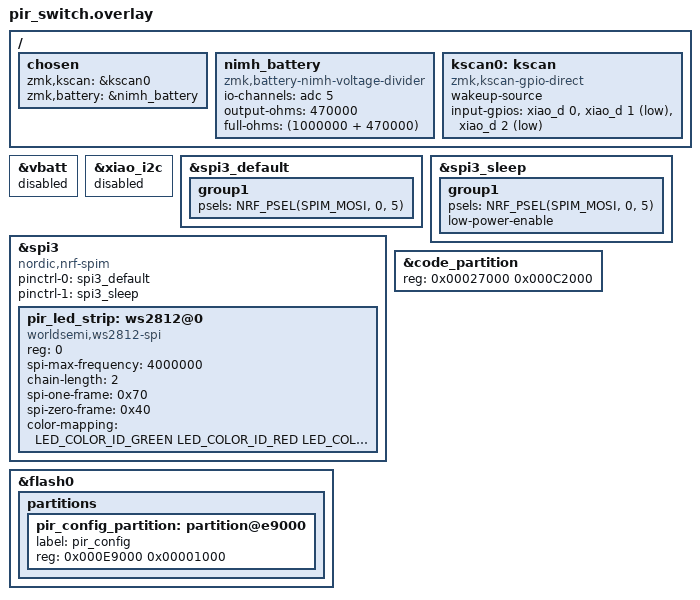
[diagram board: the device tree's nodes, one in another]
/*
 * ハードウェア定義（デバイスツリー = 「どのピンに何がつながっているか」を書くファイル）
 *
 * 配線:
 *   AM312 VCC -> XIAO BLE 3V3
 *   AM312 GND -> XIAO BLE GND
 *   AM312 OUT -> XIAO BLE D0
 *   スイッチA -> D1 と GND の間（モード1・緑）
 *   スイッチB -> D2 と GND の間（モード2・青）
 *   LED1（スイッチAの下、SK6812MINI-E）: VDD -> 3V3, GND -> GND, DIN -> D5
 *   LED2（スイッチBの下、SK6812MINI-E）: VDD -> 3V3, GND -> GND, DIN -> LED1 の DOUT
 *   昇圧モジュール（aaa-boost-module-v2）:
 *     GND -> GND, 5V -> 5V, SNS -> D3, MCU -> BAT+（XIAO 裏面）, BAT -> 電源スイッチ -> 電池+
 */

#include <dt-bindings/led/led.h>

/ {
    chosen {
        zmk,kscan = &kscan0;
        zmk,battery = &nimh_battery;
    };

    /*
     * 電池残量（エネループ1本）
     * 昇圧モジュールの SNS 端子 = 電池電圧 × 470k / (1M + 470k) を D3（P0.29 = AIN5）で測る。
     * XIAO 標準の vbatt は BAT+ の電圧（= 昇圧後の一定電圧）を測るため、残量の目安にならないので使わない。
     */
    nimh_battery: nimh_battery {
        compatible = "zmk,battery-nimh-voltage-divider";
        io-channels = <&adc 5>;
        output-ohms = <470000>;
        full-ohms = <(1000000 + 470000)>;
    };

    kscan0: kscan {
        /* キーマトリクスを使わず、1ピン = 1キーとして読む方式 */
        compatible = "zmk,kscan-gpio-direct";

        /* 省電力スリープ中でも、このピンの変化で起きるようにする */
        wakeup-source;

        /*
         * キー番号 0: センサー（D0）
         *   GPIO_ACTIVE_HIGH: 電圧がHIGHのときを「押された」と判定する
         *   内蔵プルダウン（GPIO_PULL_DOWN）はあえて付けない。
         *   AM312の出力に約20kΩの抵抗があるという情報が正しければ、
         *   内蔵抵抗（約13kΩ）と分圧されてHIGHが約1.3Vまで下がり、読めなくなるため。
         *
         * キー番号 1, 2: スイッチA（D1）, スイッチB（D2）
         *   内蔵プルアップを使い、押すと GND につながって LOW になる（= 押された）
         */
        input-gpios
            = <&xiao_d 0 GPIO_ACTIVE_HIGH>
            , <&xiao_d 1 (GPIO_ACTIVE_LOW | GPIO_PULL_UP)>
            , <&xiao_d 2 (GPIO_ACTIVE_LOW | GPIO_PULL_UP)>
            ;
    };

};

&vbatt {
    status = "disabled";
};

/* D5 は標準では I2C に割り当てられているので、LED に使うため I2C を止める */
&xiao_i2c {
    status = "disabled";
};

/*
 * スイッチの下のフルカラーLED（SK6812MINI-E × 2、数珠つなぎ）
 * SPI の MOSI 信号で WS2812 互換の信号を作る方式（ZMK の公式ドキュメントと同じ）。
 * 使うのは MOSI（D5 = P0.05）だけ。XIAO の標準定義の SCK/MISO は割り当てない。
 */
&spi3_default {
    group1 {
        psels = <NRF_PSEL(SPIM_MOSI, 0, 5)>;
    };
};

&spi3_sleep {
    group1 {
        psels = <NRF_PSEL(SPIM_MOSI, 0, 5)>;
        low-power-enable;
    };
};

&spi3 {
    compatible = "nordic,nrf-spim";
    status = "okay";
    pinctrl-0 = <&spi3_default>;
    pinctrl-1 = <&spi3_sleep>;
    pinctrl-names = "default", "sleep";

    pir_led_strip: ws2812@0 {
        compatible = "worldsemi,ws2812-spi";
        reg = <0>; /* SPI の決まりで必要（実際には使わない） */
        spi-max-frequency = <4000000>;
        chain-length = <2>; /* 0 = スイッチAの下, 1 = スイッチBの下 */
        spi-one-frame = <0x70>;
        spi-zero-frame = <0x40>;
        color-mapping = <LED_COLOR_ID_GREEN LED_COLOR_ID_RED LED_COLOR_ID_BLUE>;
    };
};

/*
 * 設定データ用の領域（4KB）
 * アプリ領域の末尾を削って確保する。設定サイトで作った .uf2 はこの領域だけを書き換える。
 * アドレスを変えた場合は docs/index.html の CONFIG_ADDR も合わせること。
 *
 * XIAO のブートローダー（Adafruit nRF52 Bootloader）は 0xEA000 以上への書き込みを
 * 受け付けない（ブートローダー手前の 40KB はアプリのデータ用として保護されている）。
 * そのため設定データは 0xEA000 より手前に置く必要がある。
 *
 *   0x00027000 アプリ（0xC2000 = 776KB、元は 788KB）
 *   0x000E9000 設定データ（4KB）
 *   0x000EA000 未使用（8KB）
 *   0x000EC000 storage（ZMKの設定・ペアリング情報、変更なし）
 */
&code_partition {
    reg = <0x00027000 0x000C2000>;
};

&flash0 {
    partitions {
        pir_config_partition: partition@e9000 {
            label = "pir_config";
            reg = <0x000E9000 0x00001000>;
        };
    };
};
